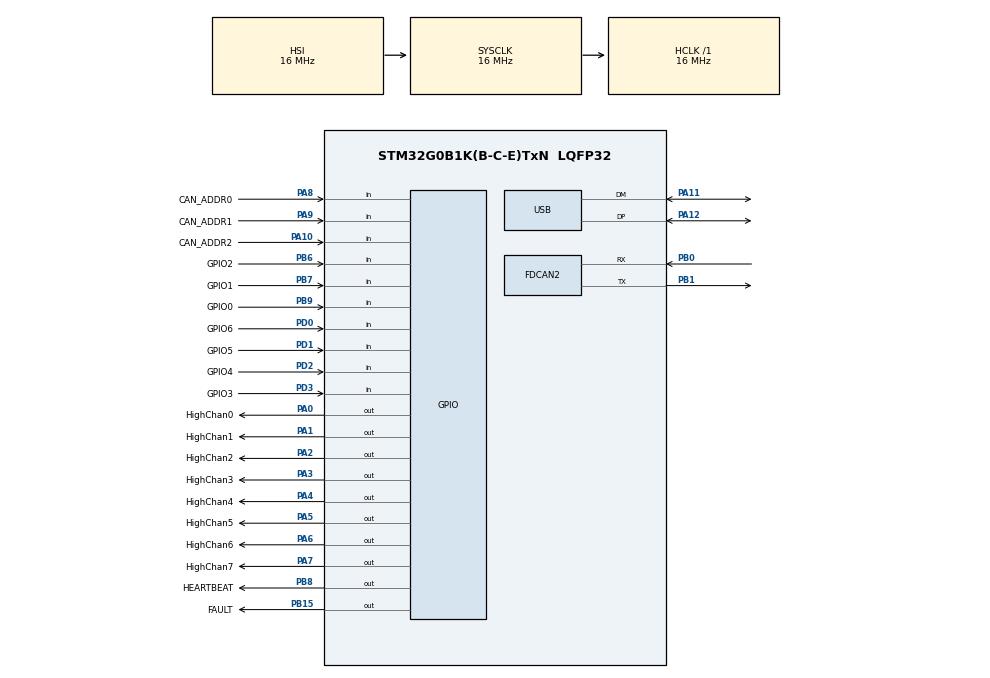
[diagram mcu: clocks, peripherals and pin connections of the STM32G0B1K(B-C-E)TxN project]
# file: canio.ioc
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FDCAN2.CalculateBaudRateNominal=333333
FDCAN2.CalculateTimeBitNominal=3000
FDCAN2.CalculateTimeQuantumNominal=1000.0
FREERTOS.Tasks01=defaultTask,24,128,StartDefaultTask,Default,NULL,Dynamic,NULL,NULL
Mcu.Family=STM32G0
Mcu.Name=STM32G0B1K(B-C-E)TxN
Mcu.Package=LQFP32
PA0.GPIO_Label=HighChan0
PA0.GPIO_PuPd=GPIO_NOPULL
PA0.Signal=GPIO_Output
PA1.GPIO_Label=HighChan1
PA1.GPIO_PuPd=GPIO_NOPULL
PA1.Signal=GPIO_Output
PA10.GPIO_Label=CAN_ADDR2
PA10.Signal=GPIO_Input
PA11\ [PA9].Mode=Device
PA11\ [PA9].Signal=USB_DM
PA12\ [PA10].Mode=Device
PA12\ [PA10].Signal=USB_DP
PA13.Mode=Serial_Wire
PA13.Signal=SYS_SWDIO
PA14-BOOT0.Mode=Serial_Wire
PA14-BOOT0.Signal=SYS_SWCLK
PA2.GPIO_Label=HighChan2
PA2.GPIO_PuPd=GPIO_NOPULL
PA2.Signal=GPIO_Output
PA3.GPIO_Label=HighChan3
PA3.GPIO_PuPd=GPIO_NOPULL
PA3.Signal=GPIO_Output
PA4.GPIO_Label=HighChan4
PA4.GPIO_PuPd=GPIO_NOPULL
PA4.Signal=GPIO_Output
PA5.GPIO_Label=HighChan5
PA5.Signal=GPIO_Output
PA6.GPIO_Label=HighChan6
PA6.Signal=GPIO_Output
PA7.GPIO_Label=HighChan7
PA7.Signal=GPIO_Output
PA8.GPIO_Label=CAN_ADDR0
PA8.Signal=GPIO_Input
PA9.GPIO_Label=CAN_ADDR1
PA9.Signal=GPIO_Input
PB0.Mode=FDCAN_Activate
PB0.Signal=FDCAN2_RX
PB1.Mode=FDCAN_Activate
PB1.Signal=FDCAN2_TX
PB15.GPIO_Label=FAULT
PB15.Signal=GPIO_Output
PB6.GPIO_Label=GPIO2
PB6.GPIO_PuPd=GPIO_PULLDOWN
PB6.Signal=GPIO_Input
PB7.GPIO_Label=GPIO1
PB7.GPIO_PuPd=GPIO_PULLDOWN
PB7.Signal=GPIO_Input
PB8.GPIO_Label=HEARTBEAT
PB8.Signal=GPIO_Output
PB9.GPIO_Label=GPIO0
PB9.GPIO_PuPd=GPIO_PULLDOWN
PB9.Signal=GPIO_Input
PC14-OSC32_IN\ (PC14).Mode=LSE-External-Oscillator
PC14-OSC32_IN\ (PC14).Signal=RCC_OSC32_IN
PC15-OSC32_OUT\ (PC15).Mode=LSE-External-Oscillator
PC15-OSC32_OUT\ (PC15).Signal=RCC_OSC32_OUT
PD0.GPIO_Label=GPIO6
PD0.GPIO_PuPd=GPIO_PULLDOWN
PD0.Signal=GPIO_Input
PD1.GPIO_Label=GPIO5
PD1.GPIO_PuPd=GPIO_PULLDOWN
PD1.Signal=GPIO_Input
PD2.GPIO_Label=GPIO4
PD2.GPIO_PuPd=GPIO_PULLDOWN
PD2.Signal=GPIO_Input
PD3.GPIO_Label=GPIO3
PD3.GPIO_PuPd=GPIO_PULLDOWN
PD3.Signal=GPIO_Input
ProjectManager.HeapSize=0x200
ProjectManager.StackSize=0x400
ProjectManager.TargetToolchain=STM32CubeIDE
RCC.AHBFreq_Value=16000000
RCC.CortexFreq_Value=16000000
RCC.EXTERNAL_CLOCK_VALUE=48000
RCC.HCLKFreq_Value=16000000
RCC.HSE_VALUE=8000000
RCC.HSI48_VALUE=48000000
RCC.HSI_VALUE=16000000
RCC.SYSCLKFreq_VALUE=16000000
RCC.USBFreq_Value=48000000
RCC.VCOOutputFreq_Value=128000000
USB_DEVICE.CLASS_NAME_FS=CDC
USB_DEVICE.VirtualMode=Cdc
USB_DEVICE.VirtualModeFS=Cdc_FS
VP_FREERTOS_VS_CMSIS_V2.Mode=CMSIS_V2
VP_SYS_VS_DBSignals.Mode=DisableDeadBatterySignals
VP_USB_DEVICE_VS_USB_DEVICE_CDC_FS.Mode=CDC_FS
board=custom

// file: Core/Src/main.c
/* USER CODE BEGIN Header */
/**
  ******************************************************************************
  * @file           : main.c
  * @brief          : Main program body
  ******************************************************************************
  * @attention
  *
  * Copyright (c) 2026 STMicroelectronics.
  * All rights reserved.
  *
  * This software is licensed under terms that can be found in the LICENSE file
  * in the root directory of this software component.
  * If no LICENSE file comes with this software, it is provided AS-IS.
  *
  ******************************************************************************
  */
/* USER CODE END Header */
#include "main.h"
#include "cmsis_os.h"
#include "usb_device.h"

/* USER CODE BEGIN Includes */
#include "relay.h"
/* USER CODE END Includes */

FDCAN_HandleTypeDef hfdcan2;

/* Definitions for defaultTask */
osThreadId_t defaultTaskHandle;
const osThreadAttr_t defaultTask_attributes = {
  .name = "defaultTask",
  .priority = (osPriority_t) osPriorityNormal,
  .stack_size = 128 * 4
};
/* USER CODE BEGIN PV */

osThreadId_t relayTaskHandle;
const osThreadAttr_t relayTask_attributes = {
	.name = "relayTask",
	.priority = (osPriority_t) osPriorityNormal,
	.stack_size = 256 * 4
};

/* USER CODE END PV */

void SystemClock_Config(void);
static void MX_GPIO_Init(void);
static void MX_FDCAN2_Init(void);
void StartDefaultTask(void *argument);

int main(void)
{

  /* MCU Configuration--------------------------------------------------------*/

  /* Reset of all peripherals, Initializes the Flash interface and the Systick. */
  HAL_Init();

  /* Configure the system clock */
  SystemClock_Config();

  /* Initialize all configured peripherals */
  MX_GPIO_Init();
  MX_FDCAN2_Init();

  /* Init scheduler */
  osKernelInitialize();

  /* Create the thread(s) */
  /* creation of defaultTask */
  defaultTaskHandle = osThreadNew(StartDefaultTask, NULL, &defaultTask_attributes);

  /* USER CODE BEGIN RTOS_THREADS */
  relayTaskHandle = osThreadNew(relay_task, NULL, &relayTask_attributes);

  /* add threads, ... */
  /* USER CODE END RTOS_THREADS */

  /* Start scheduler */
  osKernelStart();

  /* We should never get here as control is now taken by the scheduler */

  /* Infinite loop */
  while (1)
  {

  }
}

void SystemClock_Config(void)
{
  RCC_OscInitTypeDef RCC_OscInitStruct = {0};
  RCC_ClkInitTypeDef RCC_ClkInitStruct = {0};

  /** Configure the main internal regulator output voltage
  */
  HAL_PWREx_ControlVoltageScaling(PWR_REGULATOR_VOLTAGE_SCALE1);

  /** Initializes the RCC Oscillators according to the specified parameters
  * in the RCC_OscInitTypeDef structure.
  */
  RCC_OscInitStruct.OscillatorType = RCC_OSCILLATORTYPE_HSI|RCC_OSCILLATORTYPE_HSI48;
  RCC_OscInitStruct.HSIState = RCC_HSI_ON;
  RCC_OscInitStruct.HSI48State = RCC_HSI48_ON;
  RCC_OscInitStruct.HSIDiv = RCC_HSI_DIV1;
  RCC_OscInitStruct.HSICalibrationValue = RCC_HSICALIBRATION_DEFAULT;
  RCC_OscInitStruct.PLL.PLLState = RCC_PLL_NONE;
  if (HAL_RCC_OscConfig(&RCC_OscInitStruct) != HAL_OK)
  {
    Error_Handler();
  }

  /** Initializes the CPU, AHB and APB buses clocks
  */
  RCC_ClkInitStruct.ClockType = RCC_CLOCKTYPE_HCLK|RCC_CLOCKTYPE_SYSCLK
                              |RCC_CLOCKTYPE_PCLK1;
  RCC_ClkInitStruct.SYSCLKSource = RCC_SYSCLKSOURCE_HSI;
  RCC_ClkInitStruct.AHBCLKDivider = RCC_SYSCLK_DIV1;
  RCC_ClkInitStruct.APB1CLKDivider = RCC_HCLK_DIV1;

  if (HAL_RCC_ClockConfig(&RCC_ClkInitStruct, FLASH_LATENCY_0) != HAL_OK)
  {
    Error_Handler();
  }
}

static void MX_FDCAN2_Init(void)
{

  hfdcan2.Instance = FDCAN2;
  hfdcan2.Init.ClockDivider = FDCAN_CLOCK_DIV1;
  hfdcan2.Init.FrameFormat = FDCAN_FRAME_CLASSIC;
  hfdcan2.Init.Mode = FDCAN_MODE_NORMAL;
  hfdcan2.Init.AutoRetransmission = DISABLE;
  hfdcan2.Init.TransmitPause = DISABLE;
  hfdcan2.Init.ProtocolException = DISABLE;
  hfdcan2.Init.NominalPrescaler = 16;
  hfdcan2.Init.NominalSyncJumpWidth = 1;
  hfdcan2.Init.NominalTimeSeg1 = 1;
  hfdcan2.Init.NominalTimeSeg2 = 1;
  hfdcan2.Init.DataPrescaler = 1;
  hfdcan2.Init.DataSyncJumpWidth = 1;
  hfdcan2.Init.DataTimeSeg1 = 1;
  hfdcan2.Init.DataTimeSeg2 = 1;
  hfdcan2.Init.StdFiltersNbr = 0;
  hfdcan2.Init.ExtFiltersNbr = 0;
  hfdcan2.Init.TxFifoQueueMode = FDCAN_TX_FIFO_OPERATION;
  if (HAL_FDCAN_Init(&hfdcan2) != HAL_OK)
  {
    Error_Handler();
  }

}

static void MX_GPIO_Init(void)
{
  GPIO_InitTypeDef GPIO_InitStruct = {0};

  /* GPIO Ports Clock Enable */
  __HAL_RCC_GPIOB_CLK_ENABLE();
  __HAL_RCC_GPIOC_CLK_ENABLE();
  __HAL_RCC_GPIOA_CLK_ENABLE();
  __HAL_RCC_GPIOD_CLK_ENABLE();

  /*Configure GPIO pin Output Level */
  HAL_GPIO_WritePin(GPIOA, HighChan0_Pin|HighChan1_Pin|HighChan2_Pin|HighChan3_Pin
                          |HighChan4_Pin|HighChan5_Pin|HighChan6_Pin|HighChan7_Pin, GPIO_PIN_RESET);

  /*Configure GPIO pin Output Level */
  HAL_GPIO_WritePin(GPIOB, FAULT_Pin|HEARTBEAT_Pin, GPIO_PIN_RESET);

  /*Configure GPIO pins : GPIO0_Pin GPIO2_Pin GPIO1_Pin */
  GPIO_InitStruct.Pin = GPIO0_Pin|GPIO2_Pin|GPIO1_Pin;
  GPIO_InitStruct.Mode = GPIO_MODE_INPUT;
  GPIO_InitStruct.Pull = GPIO_PULLDOWN;
  HAL_GPIO_Init(GPIOB, &GPIO_InitStruct);

  /*Configure GPIO pins : HighChan0_Pin HighChan1_Pin HighChan2_Pin HighChan3_Pin
                           HighChan4_Pin HighChan5_Pin HighChan6_Pin HighChan7_Pin */
  GPIO_InitStruct.Pin = HighChan0_Pin|HighChan1_Pin|HighChan2_Pin|HighChan3_Pin
                          |HighChan4_Pin|HighChan5_Pin|HighChan6_Pin|HighChan7_Pin;
  GPIO_InitStruct.Mode = GPIO_MODE_OUTPUT_PP;
  GPIO_InitStruct.Pull = GPIO_NOPULL;
  GPIO_InitStruct.Speed = GPIO_SPEED_FREQ_LOW;
  HAL_GPIO_Init(GPIOA, &GPIO_InitStruct);

  /*Configure GPIO pins : FAULT_Pin HEARTBEAT_Pin */
  GPIO_InitStruct.Pin = FAULT_Pin|HEARTBEAT_Pin;
  GPIO_InitStruct.Mode = GPIO_MODE_OUTPUT_PP;
  GPIO_InitStruct.Pull = GPIO_NOPULL;
  GPIO_InitStruct.Speed = GPIO_SPEED_FREQ_LOW;
  HAL_GPIO_Init(GPIOB, &GPIO_InitStruct);

  /*Configure GPIO pins : CAN_ADDR0_Pin CAN_ADDR1_Pin CAN_ADDR2_Pin */
  GPIO_InitStruct.Pin = CAN_ADDR0_Pin|CAN_ADDR1_Pin|CAN_ADDR2_Pin;
  GPIO_InitStruct.Mode = GPIO_MODE_INPUT;
  GPIO_InitStruct.Pull = GPIO_NOPULL;
  HAL_GPIO_Init(GPIOA, &GPIO_InitStruct);

  /*Configure GPIO pins : GPIO6_Pin GPIO5_Pin GPIO4_Pin GPIO3_Pin */
  GPIO_InitStruct.Pin = GPIO6_Pin|GPIO5_Pin|GPIO4_Pin|GPIO3_Pin;
  GPIO_InitStruct.Mode = GPIO_MODE_INPUT;
  GPIO_InitStruct.Pull = GPIO_PULLDOWN;
  HAL_GPIO_Init(GPIOD, &GPIO_InitStruct);

}

void StartDefaultTask(void *argument)
{
  /* init code for USB_Device */
  MX_USB_Device_Init();
  for(;;)
  {
    osDelay(1);
  }
}

void Error_Handler(void)
{
  __disable_irq();
  while (1)
  {
  }
}
